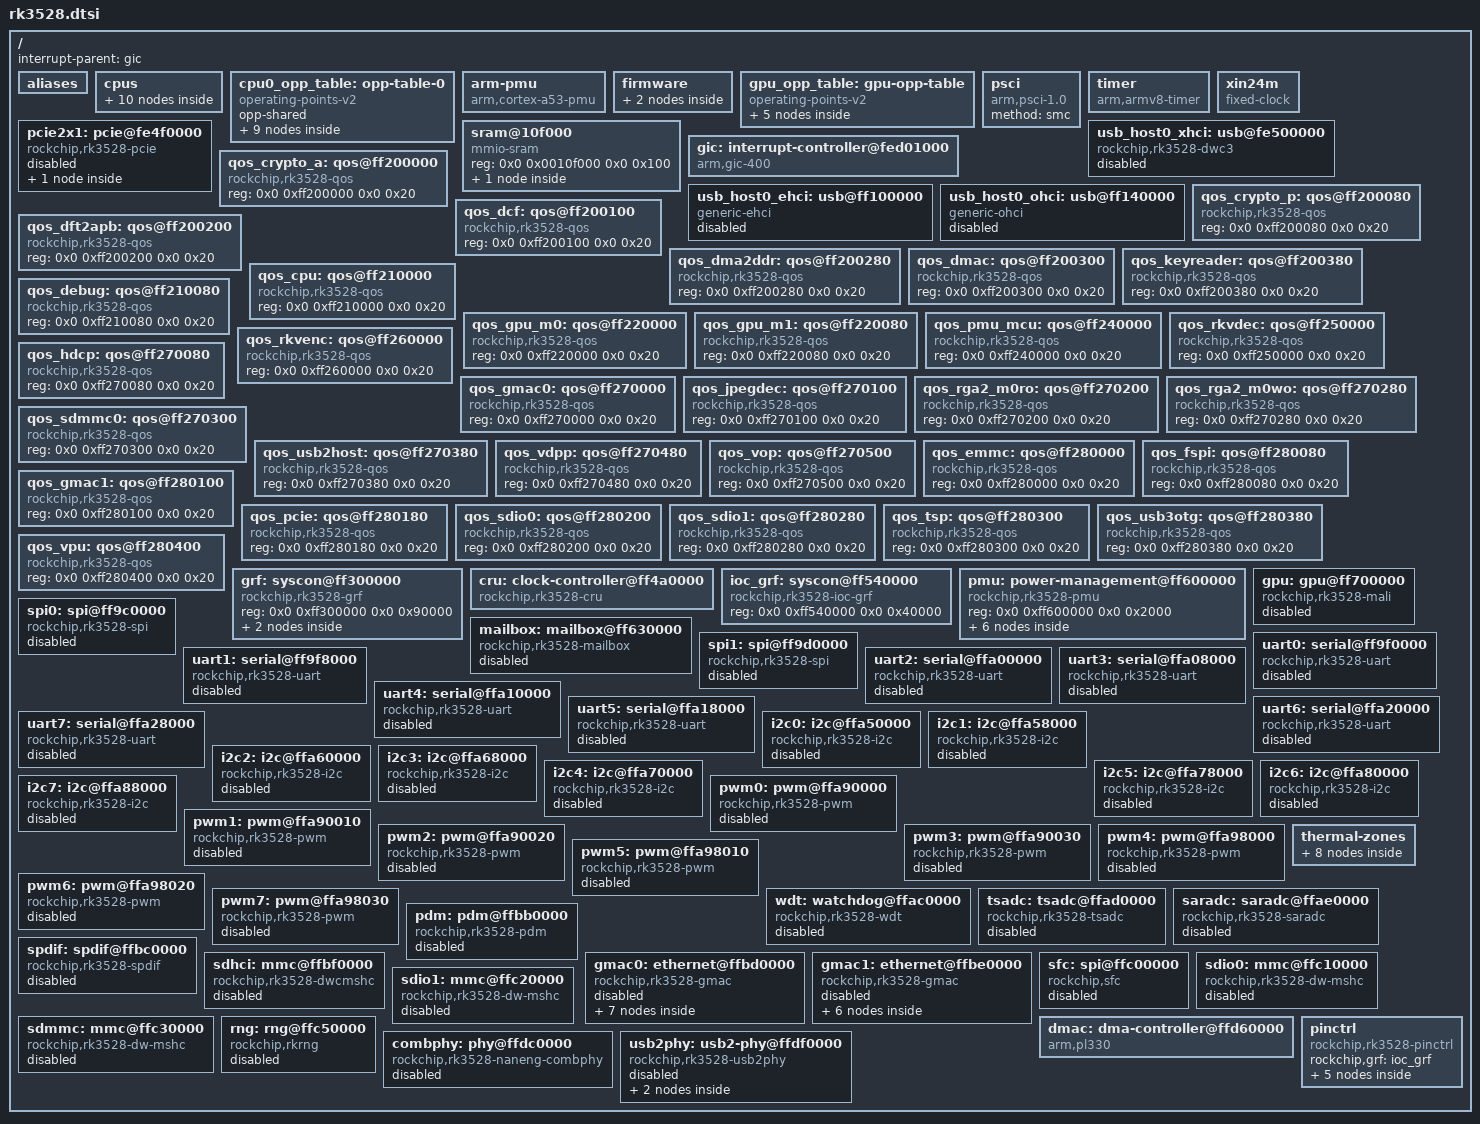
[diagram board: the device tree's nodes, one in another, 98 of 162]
// SPDX-License-Identifier: (GPL-2.0+ OR MIT)
/*
 * Copyright (c) 2022 Rockchip Electronics Co., Ltd.
 */

#include <dt-bindings/clock/rk3528-cru.h>
#include <dt-bindings/interrupt-controller/arm-gic.h>
#include <dt-bindings/interrupt-controller/irq.h>
#include <dt-bindings/phy/phy.h>
#include <dt-bindings/pinctrl/rockchip.h>
#include <dt-bindings/power/rk3528-power.h>
#include <dt-bindings/soc/rockchip,boot-mode.h>
#include <dt-bindings/thermal/thermal.h>

/ {
	interrupt-parent = <&gic>;
	#address-cells = <2>;
	#size-cells = <2>;

	aliases {
		gpio0 = &gpio0;
		gpio1 = &gpio1;
		gpio2 = &gpio2;
		gpio3 = &gpio3;
		gpio4 = &gpio4;
		i2c0 = &i2c0;
		i2c1 = &i2c1;
		i2c2 = &i2c2;
		i2c3 = &i2c3;
		i2c4 = &i2c4;
		i2c5 = &i2c5;
		i2c6 = &i2c6;
		i2c7 = &i2c7;
		serial0 = &uart0;
		serial1 = &uart1;
		serial2 = &uart2;
		serial3 = &uart3;
		serial4 = &uart4;
		serial5 = &uart5;
		serial6 = &uart6;
		serial7 = &uart7;
		spi0 = &spi0;
		spi1 = &spi1;
		spi2 = &sfc;
	};

	cpus {
		#address-cells = <2>;
		#size-cells = <0>;

		cpu-map {
			cluster0 {
				core0 {
					cpu = <&cpu0>;
				};
				core1 {
					cpu = <&cpu1>;
				};
				core2 {
					cpu = <&cpu2>;
				};
				core3 {
					cpu = <&cpu3>;
				};
			};
		};

		cpu0: cpu@0 {
			device_type = "cpu";
			compatible = "arm,cortex-a53";
			reg = <0x0 0x0>;
			clocks = <&scmi_clk SCMI_CLK_CPU>;
			assigned-clocks = <&scmi_clk SCMI_CLK_CPU>;
			assigned-clock-rates = <1200000000>;
			dynamic-power-coefficient = <147>;
			#cooling-cells = <2>;
			enable-method = "psci";
			operating-points-v2 = <&cpu0_opp_table>;
		};

		cpu1: cpu@1 {
			device_type = "cpu";
			compatible = "arm,cortex-a53";
			reg = <0x0 0x1>;
			clocks = <&scmi_clk SCMI_CLK_CPU>;
			dynamic-power-coefficient = <147>;
			#cooling-cells = <2>;
			enable-method = "psci";
			operating-points-v2 = <&cpu0_opp_table>;
		};

		cpu2: cpu@2 {
			device_type = "cpu";
			compatible = "arm,cortex-a53";
			reg = <0x0 0x2>;
			clocks = <&scmi_clk SCMI_CLK_CPU>;
			dynamic-power-coefficient = <147>;
			#cooling-cells = <2>;
			enable-method = "psci";
			operating-points-v2 = <&cpu0_opp_table>;
		};

		cpu3: cpu@3 {
			device_type = "cpu";
			compatible = "arm,cortex-a53";
			reg = <0x0 0x3>;
			clocks = <&scmi_clk SCMI_CLK_CPU>;
			dynamic-power-coefficient = <147>;
			#cooling-cells = <2>;
			enable-method = "psci";
			operating-points-v2 = <&cpu0_opp_table>;
		};
	};

	cpu0_opp_table: opp-table-0 {
		compatible = "operating-points-v2";
		opp-shared;

		opp-408000000 {
			opp-hz = /bits/ 64 <408000000>;
			opp-microvolt = <825000 825000 1100000>;
			clock-latency-ns = <40000>;
			opp-suspend;
		};

		opp-600000000 {
			opp-hz = /bits/ 64 <600000000>;
			opp-microvolt = <825000 825000 1100000>;
			clock-latency-ns = <40000>;
		};

		opp-816000000 {
			opp-hz = /bits/ 64 <816000000>;
			opp-microvolt = <825000 825000 1100000>;
			clock-latency-ns = <40000>;
		};

		opp-1008000000 {
			opp-hz = /bits/ 64 <1008000000>;
			opp-microvolt = <825000 825000 1100000>;
			clock-latency-ns = <40000>;
		};

		opp-1200000000 {
			opp-hz = /bits/ 64 <1200000000>;
			opp-microvolt = <825000 825000 1100000>;
			clock-latency-ns = <40000>;
		};

		opp-1416000000 {
			opp-hz = /bits/ 64 <1416000000>;
			opp-microvolt = <962500 962500 1100000>;
			clock-latency-ns = <40000>;
		};

		opp-1608000000 {
			opp-hz = /bits/ 64 <1608000000>;
			opp-microvolt = <1012500 1012500 1100000>;
			clock-latency-ns = <40000>;
		};

		opp-1800000000 {
			opp-hz = /bits/ 64 <1800000000>;
			opp-microvolt = <1062500 1062500 1100000>;
			clock-latency-ns = <40000>;
		};

		opp-2016000000 {
			opp-hz = /bits/ 64 <2016000000>;
			opp-microvolt = <1100000 1100000 1100000>;
			clock-latency-ns = <40000>;
		};
	};

	arm-pmu {
		compatible = "arm,cortex-a53-pmu";
		interrupts = <GIC_SPI 171 IRQ_TYPE_LEVEL_HIGH>,
			     <GIC_SPI 172 IRQ_TYPE_LEVEL_HIGH>,
			     <GIC_SPI 173 IRQ_TYPE_LEVEL_HIGH>,
			     <GIC_SPI 174 IRQ_TYPE_LEVEL_HIGH>;
		interrupt-affinity = <&cpu0>, <&cpu1>, <&cpu2>, <&cpu3>;
	};

	firmware {
		scmi: scmi {
			compatible = "arm,scmi-smc";
			arm,smc-id = <0x82000010>;
			shmem = <&scmi_shmem>;
			#address-cells = <1>;
			#size-cells = <0>;

			scmi_clk: protocol@14 {
				reg = <0x14>;
				#clock-cells = <1>;
			};
		};
	};

	gpu_opp_table: gpu-opp-table {
		compatible = "operating-points-v2";

		opp-300000000 {
			opp-hz = /bits/ 64 <300000000>;
			opp-microvolt = <875000 875000 1000000>;
		};

		opp-500000000 {
			opp-hz = /bits/ 64 <500000000>;
			opp-microvolt = <875000 875000 1000000>;
		};

		opp-600000000 {
			opp-hz = /bits/ 64 <600000000>;
			opp-microvolt = <875000 875000 1000000>;
		};

		opp-700000000 {
			opp-hz = /bits/ 64 <700000000>;
			opp-microvolt = <900000 900000 1000000>;
		};

		opp-800000000 {
			opp-hz = /bits/ 64 <800000000>;
			opp-microvolt = <950000 950000 1000000>;
		};
	};

	psci {
		compatible = "arm,psci-1.0";
		method = "smc";
	};

	timer {
		compatible = "arm,armv8-timer";
		interrupts = <GIC_PPI 13 (GIC_CPU_MASK_SIMPLE(4) | IRQ_TYPE_LEVEL_LOW)>,
			     <GIC_PPI 14 (GIC_CPU_MASK_SIMPLE(4) | IRQ_TYPE_LEVEL_LOW)>,
			     <GIC_PPI 11 (GIC_CPU_MASK_SIMPLE(4) | IRQ_TYPE_LEVEL_LOW)>,
			     <GIC_PPI 10 (GIC_CPU_MASK_SIMPLE(4) | IRQ_TYPE_LEVEL_LOW)>;
	};

	xin24m: xin24m {
		compatible = "fixed-clock";
		#clock-cells = <0>;
		clock-frequency = <24000000>;
		clock-output-names = "xin24m";
	};

	sram@10f000 {
		compatible = "mmio-sram";
		reg = <0x0 0x0010f000 0x0 0x100>;
		ranges = <0 0x0 0x0010f000 0x100>;
		#address-cells = <1>;
		#size-cells = <1>;

		scmi_shmem: sram@0 {
			compatible = "arm,scmi-shmem";
			reg = <0x0 0x100>;
		};
	};

	pcie2x1: pcie@fe4f0000 {
		compatible = "rockchip,rk3528-pcie", "snps,dw-pcie";
		reg = <0x0 0xfe000000 0x0 0x400000>,
		      <0x0 0xfe4f0000 0x0 0x010000>,
		      <0x0 0xfc000000 0x0 0x100000>;
		reg-names = "pcie-dbi", "pcie-apb", "config";
		interrupts = <GIC_SPI 158 IRQ_TYPE_LEVEL_HIGH>,
			     <GIC_SPI 157 IRQ_TYPE_LEVEL_HIGH>,
			     <GIC_SPI 156 IRQ_TYPE_LEVEL_HIGH>,
			     <GIC_SPI 155 IRQ_TYPE_LEVEL_HIGH>,
			     <GIC_SPI 154 IRQ_TYPE_LEVEL_HIGH>,
			     <GIC_SPI 153 IRQ_TYPE_LEVEL_HIGH>;
		interrupt-names = "msi", "pmc", "sys", "legacy", "msg", "err";
		bus-range = <0x0 0xff>;
		clocks = <&cru ACLK_PCIE>, <&cru HCLK_PCIE_SLV>,
			 <&cru HCLK_PCIE_DBI>, <&cru PCLK_CRU_PCIE>,
			 <&cru CLK_PCIE_AUX>, <&cru PCLK_PCIE>,
			 <&cru PCLK_PCIE_PHY>;
		clock-names = "aclk", "hclk_slv",
			      "hclk_dbi", "pclk_cru",
			      "aux", "pclk",
			      "pipe";
		device_type = "pci";
		#interrupt-cells = <1>;
		interrupt-map-mask = <0 0 0 7>;
		interrupt-map = <0 0 0 1 &pcie_intc 0>,
				<0 0 0 2 &pcie_intc 1>,
				<0 0 0 3 &pcie_intc 2>,
				<0 0 0 4 &pcie_intc 3>;
		linux,pci-domain = <0>;
		max-link-speed = <2>;
		num-ib-windows = <8>;
		num-ob-windows = <8>;
		num-viewport = <4>;
		num-lanes = <1>;
		phys = <&combphy PHY_TYPE_PCIE>;
		phy-names = "pcie-phy";
		ranges = <0x81000000 0x0 0xfc100000 0x0 0xfc100000 0x0 0x00100000
			  0x82000000 0x0 0xfc200000 0x0 0xfc200000 0x0 0x01e00000
			  0xc3000000 0x1 0x00000000 0x1 0x00000000 0x0 0x40000000>;
		resets = <&cru SRST_RESETN_PCIE_POWER_UP>, <&cru SRST_PRESETN_PCIE>,
			 <&cru SRST_PRESETN_CRU_PCIE>;
		reset-names = "pwr", "periph", "preset_cru";
		#address-cells = <3>;
		#size-cells = <2>;
		status = "disabled";

		pcie_intc: legacy-interrupt-controller {
			#address-cells = <0>;
			#interrupt-cells = <1>;
			interrupt-controller;
			interrupt-parent = <&gic>;
			interrupts = <GIC_SPI 155 IRQ_TYPE_EDGE_RISING>;
		};
	};

	usb_host0_xhci: usb@fe500000 {
		compatible = "rockchip,rk3528-dwc3", "snps,dwc3";
		reg = <0x0 0xfe500000 0x0 0x400000>;
		interrupts = <GIC_SPI 152 IRQ_TYPE_LEVEL_HIGH>;
		clocks = <&cru CLK_REF_USB3OTG>, <&cru CLK_SUSPEND_USB3OTG>,
			 <&cru ACLK_USB3OTG>;
		clock-names = "ref_clk", "suspend_clk",
			      "bus_clk";
		dr_mode = "otg";
		phys = <&usb2phy0_otg>, <&combphy PHY_TYPE_USB3>;
		phy-names = "usb2-phy", "usb3-phy";
		phy_type = "utmi_wide";
		snps,dis-del-phy-power-chg-quirk;
		snps,dis-tx-ipgap-linecheck-quirk;
		snps,dis-u2-freeclk-exists-quirk;
		snps,dis_enblslpm_quirk;
		snps,dis_u2_susphy_quirk;
		resets = <&cru SRST_ARESETN_USB3OTG>;
		reset-names = "usb3-otg";
		status = "disabled";
	};

	gic: interrupt-controller@fed01000 {
		compatible = "arm,gic-400";
		#interrupt-cells = <3>;
		#address-cells = <0>;
		interrupt-controller;
		reg = <0x0 0xfed01000 0 0x1000>,
		      <0x0 0xfed02000 0 0x2000>,
		      <0x0 0xfed04000 0 0x2000>,
		      <0x0 0xfed06000 0 0x2000>;
		interrupts = <GIC_PPI 9
		      (GIC_CPU_MASK_SIMPLE(4) | IRQ_TYPE_LEVEL_LOW)>;
	};

	usb_host0_ehci: usb@ff100000 {
		compatible = "generic-ehci";
		reg = <0x0 0xff100000 0x0 0x40000>;
		interrupts = <GIC_SPI 143 IRQ_TYPE_LEVEL_HIGH>;
		clocks = <&cru HCLK_USBHOST>,
			 <&cru HCLK_USBHOST_ARB>,
			 <&usb2phy>;
		clock-names = "usbhost", "arbiter", "utmi";
		phys = <&usb2phy0_host>;
		phy-names = "usb2-phy";
		status = "disabled";
	};

	usb_host0_ohci: usb@ff140000 {
		compatible = "generic-ohci";
		reg = <0x0 0xff140000 0x0 0x40000>;
		interrupts = <GIC_SPI 144 IRQ_TYPE_LEVEL_HIGH>;
		clocks = <&cru HCLK_USBHOST>,
			 <&cru HCLK_USBHOST_ARB>,
			 <&usb2phy>;
		clock-names = "usbhost", "arbiter", "utmi";
		phys = <&usb2phy0_host>;
		phy-names = "usb2-phy";
		status = "disabled";
	};

	qos_crypto_a: qos@ff200000 {
		compatible = "rockchip,rk3528-qos", "syscon";
		reg = <0x0 0xff200000 0x0 0x20>;
	};

	qos_crypto_p: qos@ff200080 {
		compatible = "rockchip,rk3528-qos", "syscon";
		reg = <0x0 0xff200080 0x0 0x20>;
	};

	qos_dcf: qos@ff200100 {
		compatible = "rockchip,rk3528-qos", "syscon";
		reg = <0x0 0xff200100 0x0 0x20>;
	};

	qos_dft2apb: qos@ff200200 {
		compatible = "rockchip,rk3528-qos", "syscon";
		reg = <0x0 0xff200200 0x0 0x20>;
	};

	qos_dma2ddr: qos@ff200280 {
		compatible = "rockchip,rk3528-qos", "syscon";
		reg = <0x0 0xff200280 0x0 0x20>;
	};

	qos_dmac: qos@ff200300 {
		compatible = "rockchip,rk3528-qos", "syscon";
		reg = <0x0 0xff200300 0x0 0x20>;
	};

	qos_keyreader: qos@ff200380 {
		compatible = "rockchip,rk3528-qos", "syscon";
		reg = <0x0 0xff200380 0x0 0x20>;
	};

	qos_cpu: qos@ff210000 {
		compatible = "rockchip,rk3528-qos", "syscon";
		reg = <0x0 0xff210000 0x0 0x20>;
	};

	qos_debug: qos@ff210080 {
		compatible = "rockchip,rk3528-qos", "syscon";
		reg = <0x0 0xff210080 0x0 0x20>;
	};

	qos_gpu_m0: qos@ff220000 {
		compatible = "rockchip,rk3528-qos", "syscon";
		reg = <0x0 0xff220000 0x0 0x20>;
	};

	qos_gpu_m1: qos@ff220080 {
		compatible = "rockchip,rk3528-qos", "syscon";
		reg = <0x0 0xff220080 0x0 0x20>;
	};

	qos_pmu_mcu: qos@ff240000 {
		compatible = "rockchip,rk3528-qos", "syscon";
		reg = <0x0 0xff240000 0x0 0x20>;
	};

	qos_rkvdec: qos@ff250000 {
		compatible = "rockchip,rk3528-qos", "syscon";
		reg = <0x0 0xff250000 0x0 0x20>;
	};

	qos_rkvenc: qos@ff260000 {
		compatible = "rockchip,rk3528-qos", "syscon";
		reg = <0x0 0xff260000 0x0 0x20>;
	};

	qos_gmac0: qos@ff270000 {
		compatible = "rockchip,rk3528-qos", "syscon";
		reg = <0x0 0xff270000 0x0 0x20>;
	};

	qos_hdcp: qos@ff270080 {
		compatible = "rockchip,rk3528-qos", "syscon";
		reg = <0x0 0xff270080 0x0 0x20>;
	};

	qos_jpegdec: qos@ff270100 {
		compatible = "rockchip,rk3528-qos", "syscon";
		reg = <0x0 0xff270100 0x0 0x20>;
	};

	qos_rga2_m0ro: qos@ff270200 {
		compatible = "rockchip,rk3528-qos", "syscon";
		reg = <0x0 0xff270200 0x0 0x20>;
	};

	qos_rga2_m0wo: qos@ff270280 {
		compatible = "rockchip,rk3528-qos", "syscon";
		reg = <0x0 0xff270280 0x0 0x20>;
	};

	qos_sdmmc0: qos@ff270300 {
		compatible = "rockchip,rk3528-qos", "syscon";
		reg = <0x0 0xff270300 0x0 0x20>;
	};

	qos_usb2host: qos@ff270380 {
		compatible = "rockchip,rk3528-qos", "syscon";
		reg = <0x0 0xff270380 0x0 0x20>;
	};

	qos_vdpp: qos@ff270480 {
		compatible = "rockchip,rk3528-qos", "syscon";
		reg = <0x0 0xff270480 0x0 0x20>;
	};

	qos_vop: qos@ff270500 {
		compatible = "rockchip,rk3528-qos", "syscon";
		reg = <0x0 0xff270500 0x0 0x20>;
	};

	qos_emmc: qos@ff280000 {
		compatible = "rockchip,rk3528-qos", "syscon";
		reg = <0x0 0xff280000 0x0 0x20>;
	};

	qos_fspi: qos@ff280080 {
		compatible = "rockchip,rk3528-qos", "syscon";
		reg = <0x0 0xff280080 0x0 0x20>;
	};

	qos_gmac1: qos@ff280100 {
		compatible = "rockchip,rk3528-qos", "syscon";
		reg = <0x0 0xff280100 0x0 0x20>;
	};

	qos_pcie: qos@ff280180 {
		compatible = "rockchip,rk3528-qos", "syscon";
		reg = <0x0 0xff280180 0x0 0x20>;
	};

	qos_sdio0: qos@ff280200 {
		compatible = "rockchip,rk3528-qos", "syscon";
		reg = <0x0 0xff280200 0x0 0x20>;
	};

	qos_sdio1: qos@ff280280 {
		compatible = "rockchip,rk3528-qos", "syscon";
		reg = <0x0 0xff280280 0x0 0x20>;
	};

	qos_tsp: qos@ff280300 {
		compatible = "rockchip,rk3528-qos", "syscon";
		reg = <0x0 0xff280300 0x0 0x20>;
	};

	qos_usb3otg: qos@ff280380 {
		compatible = "rockchip,rk3528-qos", "syscon";
		reg = <0x0 0xff280380 0x0 0x20>;
	};

	qos_vpu: qos@ff280400 {
		compatible = "rockchip,rk3528-qos", "syscon";
		reg = <0x0 0xff280400 0x0 0x20>;
	};

	grf: syscon@ff300000 {
		compatible = "rockchip,rk3528-grf", "syscon", "simple-mfd";
		reg = <0x0 0xff300000 0x0 0x90000>;

		grf_cru: grf-clock-controller {
			compatible = "rockchip,rk3528-grf-cru";
			#clock-cells = <1>;
		};

		reboot-mode {
			compatible = "syscon-reboot-mode";
			offset = <0x70200>;
			mode-bootloader = <BOOT_BL_DOWNLOAD>;
			mode-fastboot = <BOOT_FASTBOOT>;
			mode-loader = <BOOT_BL_DOWNLOAD>;
			mode-normal = <BOOT_NORMAL>;
			mode-recovery = <BOOT_RECOVERY>;
		};
	};

	cru: clock-controller@ff4a0000 {
		compatible = "rockchip,rk3528-cru";
		reg = <0x0 0xff4a0000 0x0 0x30000>;
		rockchip,grf = <&grf>;
		#clock-cells = <1>;
		#reset-cells = <1>;
		assigned-clocks =
			<&cru XIN_OSC0_DIV>,
			<&cru PLL_GPLL>,
			<&cru PLL_PPLL>,
			<&cru PLL_CPLL>,
			<&cru CLK_MATRIX_250M_SRC>,
			<&cru CLK_MATRIX_500M_SRC>,
			<&cru CLK_MATRIX_50M_SRC>,
			<&cru CLK_MATRIX_100M_SRC>,
			<&cru CLK_MATRIX_150M_SRC>,
			<&cru CLK_MATRIX_200M_SRC>,
			<&cru CLK_MATRIX_300M_SRC>,
			<&cru CLK_MATRIX_339M_SRC>,
			<&cru CLK_MATRIX_400M_SRC>,
			<&cru CLK_MATRIX_600M_SRC>,
			<&cru CLK_PPLL_50M_MATRIX>,
			<&cru CLK_PPLL_100M_MATRIX>,
			<&cru CLK_PPLL_125M_MATRIX>,
			<&cru ACLK_BUS_VOPGL_ROOT>,
			<&cru ACLK_VO_ROOT>,
			<&cru ACLK_VPU_ROOT>,
			<&cru ACLK_VPU_L_ROOT>;
		assigned-clock-rates =
			<32768>,
			<1188000000>,
			<1000000000>,
			<996000000>,
			<250000000>,
			<500000000>,
			<50000000>,
			<100000000>,
			<150000000>,
			<200000000>,
			<300000000>,
			<340000000>,
			<400000000>,
			<600000000>,
			<50000000>,
			<100000000>,
			<125000000>,
			<500000000>,
			<340000000>,
			<300000000>,
			<200000000>;
	};

	ioc_grf: syscon@ff540000 {
		compatible = "rockchip,rk3528-ioc-grf", "syscon";
		reg = <0x0 0xff540000 0x0 0x40000>;
	};

	pmu: power-management@ff600000 {
		compatible = "rockchip,rk3528-pmu", "syscon", "simple-mfd";
		reg = <0x0 0xff600000 0x0 0x2000>;

		power: power-controller {
			compatible = "rockchip,rk3528-power-controller";
			#power-domain-cells = <1>;
			#address-cells = <1>;
			#size-cells = <0>;

			pd_gpu@RK3528_PD_GPU {
				reg = <RK3528_PD_GPU>;
				clocks = <&cru ACLK_GPU_MALI>,
					 <&cru PCLK_GPU_ROOT>;
				pm_qos = <&qos_gpu_m0>,
					 <&qos_gpu_m1>;
			};
			pd_rkvdec@RK3528_PD_RKVDEC {
				reg = <RK3528_PD_RKVDEC>;
			};
			pd_rkvenc@RK3528_PD_RKVENC {
				reg = <RK3528_PD_RKVENC>;
			};
			pd_vo@RK3528_PD_VO {
				reg = <RK3528_PD_VO>;
			};
			pd_vpu@RK3528_PD_VPU {
				reg = <RK3528_PD_VPU>;
			};
		};
	};

	mailbox: mailbox@ff630000 {
		compatible = "rockchip,rk3528-mailbox",
			     "rockchip,rk3368-mailbox";
		reg = <0x0 0xff630000 0x0 0x200>;
		interrupts = <GIC_SPI 60 IRQ_TYPE_LEVEL_HIGH>;
		clocks = <&cru PCLK_PMU_MAILBOX>;
		clock-names = "pclk_mailbox";
		#mbox-cells = <1>;
		status = "disabled";
	};

	gpu: gpu@ff700000 {
		compatible = "rockchip,rk3528-mali", "arm,mali-450";
		reg = <0x0 0xff700000 0x0 0x40000>;
		interrupts = <GIC_SPI 88 IRQ_TYPE_LEVEL_HIGH>,
			     <GIC_SPI 89 IRQ_TYPE_LEVEL_HIGH>,
			     <GIC_SPI 86 IRQ_TYPE_LEVEL_HIGH>,
			     <GIC_SPI 92 IRQ_TYPE_LEVEL_HIGH>,
			     <GIC_SPI 93 IRQ_TYPE_LEVEL_HIGH>,
			     <GIC_SPI 90 IRQ_TYPE_LEVEL_HIGH>,
			     <GIC_SPI 91 IRQ_TYPE_LEVEL_HIGH>;
		interrupt-names = "gp",
				  "gpmmu",
				  "pp",
				  "pp0",
				  "ppmmu0",
				  "pp1",
				  "ppmmu1";
		clocks = <&cru ACLK_GPU_MALI>, <&cru PCLK_GPU_ROOT>;
		clock-names = "bus", "core";
		assigned-clocks = <&scmi_clk SCMI_CLK_GPU>;
		assigned-clock-rates = <300000000>;
		power-domains = <&power RK3528_PD_GPU>;
		operating-points-v2 = <&gpu_opp_table>;
		rockchip,grf = <&grf>;
		#cooling-cells = <2>;
		status = "disabled";
	};

	spi0: spi@ff9c0000 {
		compatible = "rockchip,rk3528-spi", "rockchip,rk3066-spi";
		reg = <0x0 0xff9c0000 0x0 0x1000>;
		interrupts = <GIC_SPI 131 IRQ_TYPE_LEVEL_HIGH>;
		#address-cells = <1>;
		#size-cells = <0>;
		clocks = <&cru CLK_SPI0>, <&cru PCLK_SPI0>, <&cru SCLK_IN_SPI0>;
		clock-names = "spiclk", "apb_pclk", "sclk_in";
		dmas = <&dmac 25>, <&dmac 24>;
		dma-names = "tx", "rx";
		pinctrl-names = "default";
		pinctrl-0 = <&spi0_csn0 &spi0_csn1 &spi0_pins>;
		status = "disabled";
	};

	spi1: spi@ff9d0000 {
		compatible = "rockchip,rk3528-spi", "rockchip,rk3066-spi";
		reg = <0x0 0xff9d0000 0x0 0x1000>;
		interrupts = <GIC_SPI 132 IRQ_TYPE_LEVEL_HIGH>;
		#address-cells = <1>;
		#size-cells = <0>;
		clocks = <&cru CLK_SPI1>, <&cru PCLK_SPI1>, <&cru SCLK_IN_SPI1>;
		clock-names = "spiclk", "apb_pclk", "sclk_in";
		dmas = <&dmac 31>, <&dmac 30>;
		dma-names = "tx", "rx";
		pinctrl-names = "default";
		pinctrl-0 = <&spi1_csn0 &spi1_csn1 &spi1_pins>;
		status = "disabled";
	};

	uart0: serial@ff9f0000 {
		compatible = "rockchip,rk3528-uart", "snps,dw-apb-uart";
		reg = <0x0 0xff9f0000 0x0 0x100>;
		interrupts = <GIC_SPI 40 IRQ_TYPE_LEVEL_HIGH>;
		clocks = <&cru SCLK_UART0>, <&cru PCLK_UART0>;
		clock-names = "baudclk", "apb_pclk";
		reg-shift = <2>;
		reg-io-width = <4>;
		dmas = <&dmac 9>, <&dmac 8>;
		status = "disabled";
	};

	uart1: serial@ff9f8000 {
		compatible = "rockchip,rk3528-uart", "snps,dw-apb-uart";
		reg = <0x0 0xff9f8000 0x0 0x100>;
		interrupts = <GIC_SPI 41 IRQ_TYPE_LEVEL_HIGH>;
		clocks = <&cru SCLK_UART1>, <&cru PCLK_UART1>;
		clock-names = "baudclk", "apb_pclk";
		reg-shift = <2>;
		reg-io-width = <4>;
		dmas = <&dmac 11>, <&dmac 10>;
		status = "disabled";
	};

	uart2: serial@ffa00000 {
		compatible = "rockchip,rk3528-uart", "snps,dw-apb-uart";
		reg = <0x0 0xffa00000 0x0 0x100>;
		interrupts = <GIC_SPI 42 IRQ_TYPE_LEVEL_HIGH>;
		clocks = <&cru SCLK_UART2>, <&cru PCLK_UART2>;
		clock-names = "baudclk", "apb_pclk";
		reg-shift = <2>;
		reg-io-width = <4>;
		dmas = <&dmac 13>, <&dmac 12>;
		status = "disabled";
	};

	uart3: serial@ffa08000 {
		compatible = "rockchip,rk3528-uart", "snps,dw-apb-uart";
		reg = <0x0 0xffa08000 0x0 0x100>;
		interrupts = <GIC_SPI 43 IRQ_TYPE_LEVEL_HIGH>;
		clocks = <&cru SCLK_UART3>, <&cru PCLK_UART3>;
		clock-names = "baudclk", "apb_pclk";
		reg-shift = <2>;
		reg-io-width = <4>;
		dmas = <&dmac 15>, <&dmac 14>;
		status = "disabled";
	};

	uart4: serial@ffa10000 {
		compatible = "rockchip,rk3528-uart", "snps,dw-apb-uart";
		reg = <0x0 0xffa10000 0x0 0x100>;
		interrupts = <GIC_SPI 44 IRQ_TYPE_LEVEL_HIGH>;
		clocks = <&cru SCLK_UART4>, <&cru PCLK_UART4>;
		clock-names = "baudclk", "apb_pclk";
		reg-shift = <2>;
		reg-io-width = <4>;
		dmas = <&dmac 17>, <&dmac 16>;
		status = "disabled";
	};

	uart5: serial@ffa18000 {
		compatible = "rockchip,rk3528-uart", "snps,dw-apb-uart";
		reg = <0x0 0xffa18000 0x0 0x100>;
		interrupts = <GIC_SPI 45 IRQ_TYPE_LEVEL_HIGH>;
		clocks = <&cru SCLK_UART5>, <&cru PCLK_UART5>;
		clock-names = "baudclk", "apb_pclk";
		reg-shift = <2>;
		reg-io-width = <4>;
		dmas = <&dmac 19>, <&dmac 18>;
		status = "disabled";
	};

	uart6: serial@ffa20000 {
		compatible = "rockchip,rk3528-uart", "snps,dw-apb-uart";
		reg = <0x0 0xffa20000 0x0 0x100>;
		interrupts = <GIC_SPI 46 IRQ_TYPE_LEVEL_HIGH>;
		clocks = <&cru SCLK_UART6>, <&cru PCLK_UART6>;
		clock-names = "baudclk", "apb_pclk";
		reg-shift = <2>;
		reg-io-width = <4>;
		dmas = <&dmac 21>, <&dmac 20>;
		status = "disabled";
	};

	uart7: serial@ffa28000 {
		compatible = "rockchip,rk3528-uart", "snps,dw-apb-uart";
		reg = <0x0 0xffa28000 0x0 0x100>;
		interrupts = <GIC_SPI 47 IRQ_TYPE_LEVEL_HIGH>;
		clocks = <&cru SCLK_UART7>, <&cru PCLK_UART7>;
		clock-names = "baudclk", "apb_pclk";
		reg-shift = <2>;
		reg-io-width = <4>;
		dmas = <&dmac 23>, <&dmac 22>;
		status = "disabled";
	};

	i2c0: i2c@ffa50000 {
		compatible = "rockchip,rk3528-i2c", "rockchip,rk3399-i2c";
		reg = <0x0 0xffa50000 0x0 0x1000>;
		clocks = <&cru CLK_I2C0>, <&cru PCLK_I2C0>;
		clock-names = "i2c", "pclk";
		interrupts = <GIC_SPI 61 IRQ_TYPE_LEVEL_HIGH>;
		pinctrl-names = "default";
		pinctrl-0 = <&i2c0m0_xfer>;
		#address-cells = <1>;
		#size-cells = <0>;
		status = "disabled";
	};

	i2c1: i2c@ffa58000 {
		compatible = "rockchip,rk3528-i2c", "rockchip,rk3399-i2c";
		reg = <0x0 0xffa58000 0x0 0x1000>;
		clocks = <&cru CLK_I2C1>, <&cru PCLK_I2C1>;
		clock-names = "i2c", "pclk";
		interrupts = <GIC_SPI 62 IRQ_TYPE_LEVEL_HIGH>;
		pinctrl-names = "default";
		pinctrl-0 = <&i2c1m0_xfer>;
		#address-cells = <1>;
		#size-cells = <0>;
		status = "disabled";
	};

	i2c2: i2c@ffa60000 {
		compatible = "rockchip,rk3528-i2c", "rockchip,rk3399-i2c";
		reg = <0x0 0xffa60000 0x0 0x1000>;
		clocks = <&cru CLK_I2C2>, <&cru PCLK_I2C2>;
		clock-names = "i2c", "pclk";
		interrupts = <GIC_SPI 63 IRQ_TYPE_LEVEL_HIGH>;
		pinctrl-names = "default";
		pinctrl-0 = <&i2c2m0_xfer>;
		#address-cells = <1>;
		#size-cells = <0>;
		status = "disabled";
	};

	i2c3: i2c@ffa68000 {
		compatible = "rockchip,rk3528-i2c", "rockchip,rk3399-i2c";
		reg = <0x0 0xffa68000 0x0 0x1000>;
		clocks = <&cru CLK_I2C3>, <&cru PCLK_I2C3>;
		clock-names = "i2c", "pclk";
		interrupts = <GIC_SPI 64 IRQ_TYPE_LEVEL_HIGH>;
		pinctrl-names = "default";
		pinctrl-0 = <&i2c3m0_xfer>;
		#address-cells = <1>;
		#size-cells = <0>;
		status = "disabled";
	};

	i2c4: i2c@ffa70000 {
		compatible = "rockchip,rk3528-i2c", "rockchip,rk3399-i2c";
		reg = <0x0 0xffa70000 0x0 0x1000>;
		clocks = <&cru CLK_I2C4>, <&cru PCLK_I2C4>;
		clock-names = "i2c", "pclk";
		interrupts = <GIC_SPI 65 IRQ_TYPE_LEVEL_HIGH>;
		pinctrl-names = "default";
		pinctrl-0 = <&i2c4_xfer>;
		#address-cells = <1>;
		#size-cells = <0>;
		status = "disabled";
	};

	i2c5: i2c@ffa78000 {
		compatible = "rockchip,rk3528-i2c", "rockchip,rk3399-i2c";
		reg = <0x0 0xffa78000 0x0 0x1000>;
		clocks = <&cru CLK_I2C5>, <&cru PCLK_I2C5>;
		clock-names = "i2c", "pclk";
		interrupts = <GIC_SPI 66 IRQ_TYPE_LEVEL_HIGH>;
		pinctrl-names = "default";
		pinctrl-0 = <&i2c5m0_xfer>;
		#address-cells = <1>;
		#size-cells = <0>;
		status = "disabled";
	};

	i2c6: i2c@ffa80000 {
		compatible = "rockchip,rk3528-i2c", "rockchip,rk3399-i2c";
		reg = <0x0 0xffa80000 0x0 0x1000>;
		clocks = <&cru CLK_I2C6>, <&cru PCLK_I2C6>;
		clock-names = "i2c", "pclk";
		interrupts = <GIC_SPI 67 IRQ_TYPE_LEVEL_HIGH>;
		pinctrl-names = "default";
		pinctrl-0 = <&i2c6m0_xfer>;
		#address-cells = <1>;
		#size-cells = <0>;
		status = "disabled";
	};

	i2c7: i2c@ffa88000 {
		compatible = "rockchip,rk3528-i2c", "rockchip,rk3399-i2c";
		reg = <0x0 0xffa88000 0x0 0x1000>;
		clocks = <&cru CLK_I2C7>, <&cru PCLK_I2C7>;
		clock-names = "i2c", "pclk";
		interrupts = <GIC_SPI 68 IRQ_TYPE_LEVEL_HIGH>;
		pinctrl-names = "default";
		pinctrl-0 = <&i2c7_xfer>;
		#address-cells = <1>;
		#size-cells = <0>;
		status = "disabled";
	};

	pwm0: pwm@ffa90000 {
		compatible = "rockchip,rk3528-pwm", "rockchip,rk3328-pwm";
		reg = <0x0 0xffa90000 0x0 0x10>;
		#pwm-cells = <3>;
		pinctrl-names = "active";
		pinctrl-0 = <&pwm0m0_pins>;
		clocks = <&cru CLK_PWM0>, <&cru PCLK_PWM0>;
		clock-names = "pwm", "pclk";
		status = "disabled";
	};

	pwm1: pwm@ffa90010 {
		compatible = "rockchip,rk3528-pwm", "rockchip,rk3328-pwm";
		reg = <0x0 0xffa90010 0x0 0x10>;
		#pwm-cells = <3>;
		pinctrl-names = "active";
		pinctrl-0 = <&pwm1m0_pins>;
		clocks = <&cru CLK_PWM0>, <&cru PCLK_PWM0>;
		clock-names = "pwm", "pclk";
		status = "disabled";
	};

	pwm2: pwm@ffa90020 {
		compatible = "rockchip,rk3528-pwm", "rockchip,rk3328-pwm";
		reg = <0x0 0xffa90020 0x0 0x10>;
		#pwm-cells = <3>;
		pinctrl-names = "active";
		pinctrl-0 = <&pwm2m0_pins>;
		clocks = <&cru CLK_PWM0>, <&cru PCLK_PWM0>;
		clock-names = "pwm", "pclk";
		status = "disabled";
	};

	pwm3: pwm@ffa90030 {
		compatible = "rockchip,rk3528-pwm", "rockchip,rk3328-pwm";
		reg = <0x0 0xffa90030 0x0 0x10>;
		interrupts = <GIC_SPI 53 IRQ_TYPE_LEVEL_HIGH>,
			     <GIC_SPI 54 IRQ_TYPE_LEVEL_HIGH>;
		#pwm-cells = <3>;
		pinctrl-names = "active";
		pinctrl-0 = <&pwm3m0_pins>;
		clocks = <&cru CLK_PWM0>, <&cru PCLK_PWM0>;
		clock-names = "pwm", "pclk";
		status = "disabled";
	};

	pwm4: pwm@ffa98000 {
		compatible = "rockchip,rk3528-pwm", "rockchip,rk3328-pwm";
		reg = <0x0 0xffa98000 0x0 0x10>;
		#pwm-cells = <3>;
		pinctrl-names = "active";
		pinctrl-0 = <&pwm4m0_pins>;
		clocks = <&cru CLK_PWM1>, <&cru PCLK_PWM1>;
		clock-names = "pwm", "pclk";
		status = "disabled";
	};

	pwm5: pwm@ffa98010 {
		compatible = "rockchip,rk3528-pwm", "rockchip,rk3328-pwm";
		reg = <0x0 0xffa98010 0x0 0x10>;
		#pwm-cells = <3>;
		pinctrl-names = "active";
		pinctrl-0 = <&pwm5m0_pins>;
		clocks = <&cru CLK_PWM1>, <&cru PCLK_PWM1>;
		clock-names = "pwm", "pclk";
		status = "disabled";
	};

	pwm6: pwm@ffa98020 {
		compatible = "rockchip,rk3528-pwm", "rockchip,rk3328-pwm";
		reg = <0x0 0xffa98020 0x0 0x10>;
		#pwm-cells = <3>;
		pinctrl-names = "active";
		pinctrl-0 = <&pwm6m0_pins>;
		clocks = <&cru CLK_PWM1>, <&cru PCLK_PWM1>;
		clock-names = "pwm", "pclk";
		status = "disabled";
	};

	pwm7: pwm@ffa98030 {
		compatible = "rockchip,rk3528-pwm", "rockchip,rk3328-pwm";
		reg = <0x0 0xffa98030 0x0 0x10>;
		interrupts = <GIC_SPI 55 IRQ_TYPE_LEVEL_HIGH>,
			     <GIC_SPI 56 IRQ_TYPE_LEVEL_HIGH>;
		#pwm-cells = <3>;
		pinctrl-names = "active";
		pinctrl-0 = <&pwm7m0_pins>;
		clocks = <&cru CLK_PWM1>, <&cru PCLK_PWM1>;
		clock-names = "pwm", "pclk";
		status = "disabled";
	};

	wdt: watchdog@ffac0000 {
		compatible = "rockchip,rk3528-wdt", "snps,dw-wdt";
		reg = <0x0 0xffac0000 0x0 0x100>;
		clocks = <&cru TCLK_WDT_NS>, <&cru PCLK_WDT_NS>;
		clock-names = "tclk", "pclk";
		interrupts = <GIC_SPI 28 IRQ_TYPE_LEVEL_HIGH>;
		status = "disabled";
	};

	thermal-zones {
		soc_thermal: soc-thermal {
			polling-delay-passive = <20>;
			polling-delay = <1000>;
			sustainable-power = <638>;

			thermal-sensors = <&tsadc 0>;

			trips {
				threshold: trip-point-0 {
					temperature = <95000>;
					hysteresis = <2000>;
					type = "passive";
				};
				target: trip-point-1 {
					temperature = <110000>;
					hysteresis = <2000>;
					type = "passive";
				};
				soc_crit: soc-crit {
					temperature = <120000>;
					hysteresis = <2000>;
					type = "critical";
				};
			};

			cooling-maps {
				map0 {
					trip = <&target>;
					cooling-device = <&cpu0 THERMAL_NO_LIMIT THERMAL_NO_LIMIT>,
							 <&cpu1 THERMAL_NO_LIMIT THERMAL_NO_LIMIT>,
							 <&cpu2 THERMAL_NO_LIMIT THERMAL_NO_LIMIT>,
							 <&cpu3 THERMAL_NO_LIMIT THERMAL_NO_LIMIT>;
					contribution = <1024>;
				};
				map1 {
					trip = <&target>;
					cooling-device = <&gpu THERMAL_NO_LIMIT THERMAL_NO_LIMIT>;
					contribution = <1024>;
				};
			};
		};
	};

	tsadc: tsadc@ffad0000 {
		compatible = "rockchip,rk3528-tsadc";
		reg = <0x0 0xffad0000 0x0 0x400>;
		rockchip,grf = <&grf>;
		interrupts = <GIC_SPI 139 IRQ_TYPE_LEVEL_HIGH>;
		clocks = <&cru CLK_TSADC>, <&cru CLK_TSADC_TSEN>, <&cru PCLK_TSADC>;
		clock-names = "tsadc", "tsadc_tsen", "apb_pclk";
		assigned-clocks = <&cru CLK_TSADC>, <&cru CLK_TSADC_TSEN>;
		assigned-clock-rates = <1200000>, <12000000>;
		resets = <&cru SRST_RESETN_TSADC>, <&cru SRST_PRESETN_TSADC>;
		reset-names = "tsadc", "tsadc-apb";
		rockchip,hw-tshut-temp = <120000>;
		rockchip,hw-tshut-mode = <0>;
		rockchip,hw-tshut-polarity = <0>;
		#thermal-sensor-cells = <1>;
		status = "disabled";
	};

	saradc: saradc@ffae0000 {
		compatible = "rockchip,rk3528-saradc";
		reg = <0x0 0xffae0000 0x0 0x10000>;
		interrupts = <GIC_SPI 140 IRQ_TYPE_LEVEL_HIGH>;
		clocks = <&cru CLK_SARADC>, <&cru PCLK_SARADC>;
		clock-names = "saradc", "apb_pclk";
		resets = <&cru SRST_PRESETN_SARADC>;
		reset-names = "saradc-apb";
		#io-channel-cells = <1>;
		status = "disabled";
	};

	pdm: pdm@ffbb0000 {
		compatible = "rockchip,rk3528-pdm", "rockchip,rk3568-pdm";
		reg = <0x0 0xffbb0000 0x0 0x1000>;
		clocks = <&cru MCLK_PDM>, <&cru HCLK_PDM>;
		clock-names = "pdm_clk", "pdm_hclk";
		dmas = <&dmac 6>;
		dma-names = "rx";
		pinctrl-names = "default";
		pinctrl-0 = <&pdm_clk0
			     &pdm_clk1
			     &pdm_sdi0
			     &pdm_sdi1
			     &pdm_sdi2
			     &pdm_sdi3>;
		#sound-dai-cells = <0>;
		status = "disabled";
	};

	spdif: spdif@ffbc0000 {
		compatible = "rockchip,rk3528-spdif", "rockchip,rk3568-spdif";
		reg = <0x0 0xffbc0000 0x0 0x1000>;
		interrupts = <GIC_SPI 130 IRQ_TYPE_LEVEL_HIGH>;
		clock-names = "mclk", "hclk";
		clocks = <&cru MCLK_SPDIF>, <&cru HCLK_SPDIF>;
		dmas = <&dmac 7>;
		dma-names = "tx";
		pinctrl-names = "default";
		pinctrl-0 = <&spdifm0_pins>;
		#sound-dai-cells = <0>;
		status = "disabled";
	};

	gmac0: ethernet@ffbd0000 {
		compatible = "rockchip,rk3528-gmac", "snps,dwmac-4.20a";
		reg = <0x0 0xffbd0000 0x0 0x10000>;
		interrupts = <GIC_SPI 113 IRQ_TYPE_LEVEL_HIGH>,
			     <GIC_SPI 116 IRQ_TYPE_LEVEL_HIGH>;
		interrupt-names = "macirq", "eth_wake_irq";
		clocks = <&cru CLK_GMAC0_SRC>, <&cru CLK_GMAC0_RMII_50M>,
			 <&cru CLK_GMAC0_RX>, <&cru CLK_GMAC0_TX>,
			 <&cru PCLK_MAC_VO>, <&cru ACLK_MAC_VO>;
		clock-names = "stmmaceth", "clk_mac_ref",
			      "mac_clk_rx", "mac_clk_tx",
			      "pclk_mac", "aclk_mac";
		resets = <&cru SRST_ARESETN_MAC_VO>;
		reset-names = "stmmaceth";
		rockchip,grf = <&grf>;
		snps,axi-config = <&gmac0_stmmac_axi_setup>;
		snps,mixed-burst;
		snps,mtl-rx-config = <&gmac0_mtl_rx_setup>;
		snps,mtl-tx-config = <&gmac0_mtl_tx_setup>;
		snps,tso;
		phy-mode = "rmii";
		clock_in_out = "input";
		phy-handle = <&rmii0_phy>;
		status = "disabled";

		mdio0: mdio {
			compatible = "snps,dwmac-mdio";
			#address-cells = <0x1>;
			#size-cells = <0x0>;

			rmii0_phy: ethernet-phy@2 {
				compatible = "ethernet-phy-ieee802.3-c22";
				reg = <2>;
				clocks = <&cru CLK_MACPHY>;
				resets = <&cru SRST_RESETN_MACPHY>;
			};
		};

		gmac0_stmmac_axi_setup: stmmac-axi-config {
			snps,blen = <0 0 0 0 16 8 4>;
			snps,rd_osr_lmt = <8>;
			snps,wr_osr_lmt = <4>;
		};

		gmac0_mtl_rx_setup: rx-queues-config {
			snps,rx-queues-to-use = <1>;
			queue0 {};
		};

		gmac0_mtl_tx_setup: tx-queues-config {
			snps,tx-queues-to-use = <1>;
			queue0 {};
		};
	};

	gmac1: ethernet@ffbe0000 {
		compatible = "rockchip,rk3528-gmac", "snps,dwmac-4.20a";
		reg = <0x0 0xffbe0000 0x0 0x10000>;
		interrupts = <GIC_SPI 121 IRQ_TYPE_LEVEL_HIGH>,
			     <GIC_SPI 124 IRQ_TYPE_LEVEL_HIGH>;
		interrupt-names = "macirq", "eth_wake_irq";
		clocks = <&cru CLK_GMAC1_SRC_VPU>, <&cru CLK_GMAC1_RMII_VPU>,
			 <&cru PCLK_MAC_VPU>, <&cru ACLK_MAC_VPU>;
		clock-names = "stmmaceth", "clk_mac_ref",
			      "pclk_mac", "aclk_mac";
		resets = <&cru SRST_ARESETN_MAC>;
		reset-names = "stmmaceth";
		rockchip,grf = <&grf>;
		snps,axi-config = <&gmac1_stmmac_axi_setup>;
		snps,mixed-burst;
		snps,mtl-rx-config = <&gmac1_mtl_rx_setup>;
		snps,mtl-tx-config = <&gmac1_mtl_tx_setup>;
		snps,tso;
		status = "disabled";

		mdio1: mdio {
			compatible = "snps,dwmac-mdio";
			#address-cells = <0x1>;
			#size-cells = <0x0>;
		};

		gmac1_stmmac_axi_setup: stmmac-axi-config {
			snps,wr_osr_lmt = <4>;
			snps,rd_osr_lmt = <8>;
			snps,blen = <0 0 0 0 16 8 4>;
		};

		gmac1_mtl_rx_setup: rx-queues-config {
			snps,rx-queues-to-use = <1>;
			queue0 {};
		};

		gmac1_mtl_tx_setup: tx-queues-config {
			snps,tx-queues-to-use = <1>;
			queue0 {};
		};
	};

	sdhci: mmc@ffbf0000 {
		compatible = "rockchip,rk3528-dwcmshc";
		reg = <0x0 0xffbf0000 0x0 0x10000>;
		interrupts = <GIC_SPI 136 IRQ_TYPE_LEVEL_HIGH>;
		assigned-clocks = <&cru BCLK_EMMC>, <&cru TCLK_EMMC>, <&cru CCLK_SRC_EMMC>;
		assigned-clock-rates = <200000000>, <24000000>, <200000000>;
		clocks = <&cru CCLK_SRC_EMMC>, <&cru HCLK_EMMC>,
			 <&cru ACLK_EMMC>, <&cru BCLK_EMMC>,
			 <&cru TCLK_EMMC>;
		clock-names = "core", "bus", "axi", "block", "timer";
		resets = <&cru SRST_CRESETN_EMMC>, <&cru SRST_HRESETN_EMMC>,
			 <&cru SRST_ARESETN_EMMC>, <&cru SRST_BRESETN_EMMC>,
			 <&cru SRST_TRESETN_EMMC>;
		reset-names = "core", "bus", "axi", "block", "timer";
		max-frequency = <200000000>;
		status = "disabled";
	};

	sfc: spi@ffc00000 {
		compatible = "rockchip,sfc";
		reg = <0x0 0xffc00000 0x0 0x4000>;
		interrupts = <GIC_SPI 135 IRQ_TYPE_LEVEL_HIGH>;
		clocks = <&cru SCLK_SFC>, <&cru HCLK_SFC>;
		clock-names = "clk_sfc", "hclk_sfc";
		assigned-clocks = <&cru SCLK_SFC>;
		assigned-clock-rates = <100000000>;
		#address-cells = <1>;
		#size-cells = <0>;
		status = "disabled";
	};

	sdio0: mmc@ffc10000 {
		compatible = "rockchip,rk3528-dw-mshc",
			     "rockchip,rk3288-dw-mshc";
		reg = <0x0 0xffc10000 0x0 0x4000>;
		interrupts = <GIC_SPI 137 IRQ_TYPE_LEVEL_HIGH>;
		clocks = <&cru HCLK_SDIO0>, <&cru CCLK_SRC_SDIO0>,
			 <&grf_cru SCLK_SDIO0_DRV>, <&grf_cru SCLK_SDIO0_SAMPLE>;
		clock-names = "biu", "ciu", "ciu-drive", "ciu-sample";
		fifo-depth = <0x100>;
		max-frequency = <150000000>;
		resets = <&cru SRST_HRESETN_SDIO0>;
		reset-names = "reset";
		status = "disabled";
	};

	sdio1: mmc@ffc20000 {
		compatible = "rockchip,rk3528-dw-mshc",
			     "rockchip,rk3288-dw-mshc";
		reg = <0x0 0xffc20000 0x0 0x4000>;
		interrupts = <GIC_SPI 138 IRQ_TYPE_LEVEL_HIGH>;
		clocks = <&cru HCLK_SDIO1>, <&cru CCLK_SRC_SDIO1>,
			 <&grf_cru SCLK_SDIO1_DRV>, <&grf_cru SCLK_SDIO1_SAMPLE>;
		clock-names = "biu", "ciu", "ciu-drive", "ciu-sample";
		fifo-depth = <0x100>;
		max-frequency = <150000000>;
		resets = <&cru SRST_HRESETN_SDIO1>;
		reset-names = "reset";
		status = "disabled";
	};

	sdmmc: mmc@ffc30000 {
		compatible = "rockchip,rk3528-dw-mshc",
			     "rockchip,rk3288-dw-mshc";
		reg = <0x0 0xffc30000 0x0 0x4000>;
		interrupts = <GIC_SPI 133 IRQ_TYPE_LEVEL_HIGH>;
		clocks = <&cru HCLK_SDMMC0>, <&cru CCLK_SRC_SDMMC0>,
			 <&grf_cru SCLK_SDMMC_DRV>, <&grf_cru SCLK_SDMMC_SAMPLE>;
		clock-names = "biu", "ciu", "ciu-drive", "ciu-sample";
		fifo-depth = <0x100>;
		max-frequency = <150000000>;
		resets = <&cru SRST_HRESETN_SDMMC0>;
		reset-names = "reset";
		rockchip,use-v2-tuning;
		status = "disabled";
	};

	rng: rng@ffc50000 {
		compatible = "rockchip,rkrng";
		reg = <0x0 0xffc50000 0x0 0x200>;
		interrupts = <GIC_SPI 23 IRQ_TYPE_LEVEL_HIGH>;
		clocks = <&scmi_clk SCMI_HCLK_TRNG>;
		clock-names = "hclk_trng";
		resets = <&cru SRST_HRESETN_TRNG_NS>;
		reset-names = "reset";
		status = "disabled";
	};

	dmac: dma-controller@ffd60000 {
		compatible = "arm,pl330", "arm,primecell";
		reg = <0x0 0xffd60000 0x0 0x4000>;
		interrupts = <GIC_SPI 0 IRQ_TYPE_LEVEL_HIGH>,
			     <GIC_SPI 1 IRQ_TYPE_LEVEL_HIGH>,
			     <GIC_SPI 2 IRQ_TYPE_LEVEL_HIGH>,
			     <GIC_SPI 3 IRQ_TYPE_LEVEL_HIGH>,
			     <GIC_SPI 4 IRQ_TYPE_LEVEL_HIGH>,
			     <GIC_SPI 5 IRQ_TYPE_LEVEL_HIGH>,
			     <GIC_SPI 6 IRQ_TYPE_LEVEL_HIGH>,
			     <GIC_SPI 7 IRQ_TYPE_LEVEL_HIGH>,
			     <GIC_SPI 16 IRQ_TYPE_LEVEL_HIGH>;
		arm,pl330-periph-burst;
		clocks = <&cru ACLK_DMAC>;
		clock-names = "apb_pclk";
		#dma-cells = <1>;
	};

	combphy: phy@ffdc0000 {
		compatible = "rockchip,rk3528-naneng-combphy";
		reg = <0x0 0xffdc0000 0x0 0x10000>;
		clocks = <&cru CLK_REF_PCIE_INNER_PHY>, <&cru PCLK_PCIE_PHY>, <&cru PCLK_PIPE_GRF>;
		clock-names = "ref", "apb", "pipe";
		assigned-clocks = <&cru CLK_REF_PCIE_INNER_PHY>;
		assigned-clock-rates = <100000000>;
		resets = <&cru SRST_PRESETN_PCIE_PHY>, <&cru SRST_RESETN_PCIE_PIPE_PHY>;
		reset-names = "apb", "phy";
		rockchip,pipe-grf = <&grf>;
		rockchip,pipe-phy-grf = <&grf>;
		#phy-cells = <1>;
		status = "disabled";
	};

	usb2phy: usb2-phy@ffdf0000 {
		compatible = "rockchip,rk3528-usb2phy";
		reg = <0x0 0xffdf0000 0x0 0x10000>;
		clocks = <&cru CLK_REF_USBPHY>, <&cru PCLK_USBPHY>;
		clock-names = "phyclk", "apb_pclk";
		rockchip,usbgrf = <&grf>;
		#clock-cells = <0>;
		status = "disabled";

		usb2phy0_otg: otg-port {
			#phy-cells = <0>;
			interrupts = <GIC_SPI 146 IRQ_TYPE_LEVEL_HIGH>,
				     <GIC_SPI 147 IRQ_TYPE_LEVEL_HIGH>,
				     <GIC_SPI 148 IRQ_TYPE_LEVEL_HIGH>;
			interrupt-names = "otg-bvalid",
					  "otg-id",
					  "linestate";
			status = "disabled";
		};

		usb2phy0_host: host-port {
			#phy-cells = <0>;
			interrupts = <GIC_SPI 150 IRQ_TYPE_LEVEL_HIGH>;
			interrupt-names = "linestate";
			status = "disabled";
		};
	};

	pinctrl: pinctrl {
		compatible = "rockchip,rk3528-pinctrl";
		rockchip,grf = <&ioc_grf>;
		#address-cells = <2>;
		#size-cells = <2>;
		ranges;

		gpio0: gpio@ff610000 {
			compatible = "rockchip,gpio-bank";
			reg = <0x0 0xff610000 0x0 0x200>;
			interrupts = <GIC_SPI 71 IRQ_TYPE_LEVEL_HIGH>;
			clocks = <&cru PCLK_GPIO0>, <&cru DBCLK_GPIO0>;
			gpio-controller;
			#gpio-cells = <2>;
			gpio-ranges = <&pinctrl 0 0 32>;
			interrupt-controller;
			#interrupt-cells = <2>;
		};

		gpio1: gpio@ffaf0000 {
			compatible = "rockchip,gpio-bank";
			reg = <0x0 0xffaf0000 0x0 0x200>;
			interrupts = <GIC_SPI 73 IRQ_TYPE_LEVEL_HIGH>;
			clocks = <&cru PCLK_GPIO1>, <&cru DBCLK_GPIO1>;
			gpio-controller;
			#gpio-cells = <2>;
			gpio-ranges = <&pinctrl 0 32 32>;
			interrupt-controller;
			#interrupt-cells = <2>;
		};

		gpio2: gpio@ffb00000 {
			compatible = "rockchip,gpio-bank";
			reg = <0x0 0xffb00000 0x0 0x200>;
			interrupts = <GIC_SPI 75 IRQ_TYPE_LEVEL_HIGH>;
			clocks = <&cru PCLK_GPIO2>, <&cru DBCLK_GPIO2>;
			gpio-controller;
			#gpio-cells = <2>;
			gpio-ranges = <&pinctrl 0 64 32>;
			interrupt-controller;
			#interrupt-cells = <2>;
		};

		gpio3: gpio@ffb10000 {
			compatible = "rockchip,gpio-bank";
			reg = <0x0 0xffb10000 0x0 0x200>;
			interrupts = <GIC_SPI 76 IRQ_TYPE_LEVEL_HIGH>;
			clocks = <&cru PCLK_GPIO3>, <&cru DBCLK_GPIO3>;
			gpio-controller;
			#gpio-cells = <2>;
			gpio-ranges = <&pinctrl 0 96 32>;
			interrupt-controller;
			#interrupt-cells = <2>;
		};

		gpio4: gpio@ffb20000 {
			compatible = "rockchip,gpio-bank";
			reg = <0x0 0xffb20000 0x0 0x200>;
			interrupts = <GIC_SPI 78 IRQ_TYPE_LEVEL_HIGH>;
			clocks = <&cru PCLK_GPIO4>, <&cru DBCLK_GPIO4>;
			gpio-controller;
			#gpio-cells = <2>;
			gpio-ranges = <&pinctrl 0 128 32>;
			interrupt-controller;
			#interrupt-cells = <2>;
		};
	};
};

#include "rk3528-pinctrl.dtsi"
